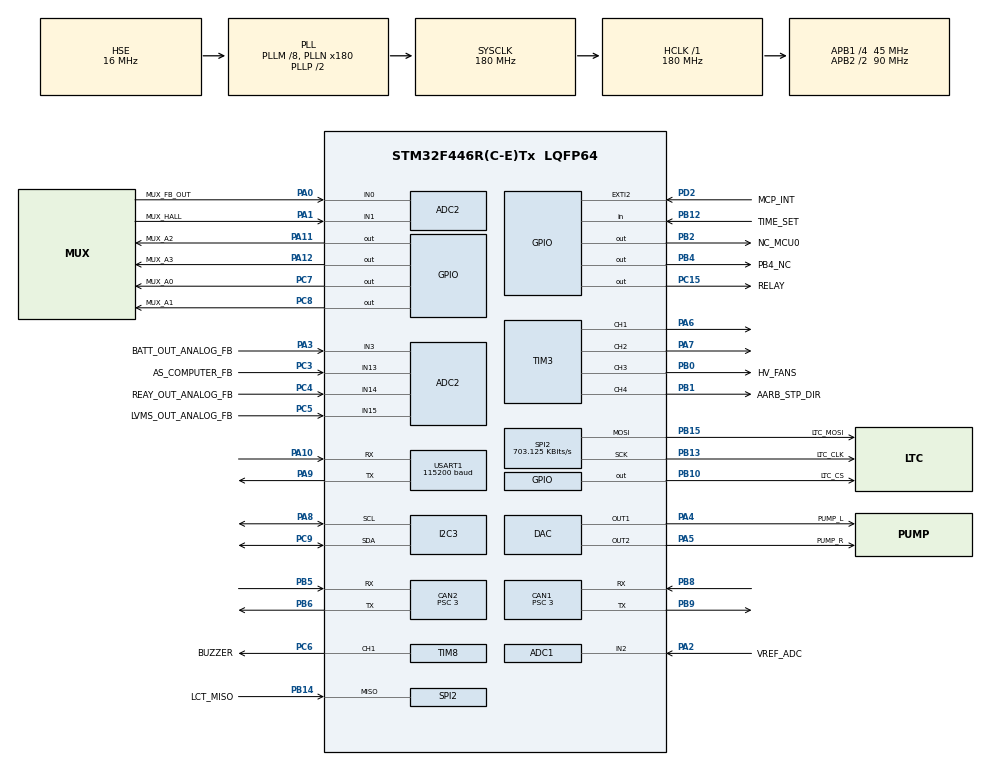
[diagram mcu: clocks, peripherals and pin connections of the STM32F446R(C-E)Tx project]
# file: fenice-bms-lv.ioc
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ADC1.Channel-0\#ChannelRegularConversion=ADC_CHANNEL_VREFINT
ADC1.Channel-1\#ChannelRegularConversion=ADC_CHANNEL_2
ADC1.ContinuousConvMode=DISABLE
ADC1.DMAContinuousRequests=ENABLE
ADC1.EOCSelection=ADC_EOC_SEQ_CONV
ADC1.ExternalTrigConv=ADC_EXTERNALTRIGCONV_T1_CC1
ADC1.NbrOfConversion=2
ADC1.NbrOfConversionFlag=1
ADC1.Rank-0\#ChannelRegularConversion=1
ADC1.Rank-1\#ChannelRegularConversion=2
ADC1.SamplingTime-0\#ChannelRegularConversion=ADC_SAMPLETIME_144CYCLES
ADC1.SamplingTime-1\#ChannelRegularConversion=ADC_SAMPLETIME_144CYCLES
ADC1.master=1
ADC2.Channel-0\#ChannelRegularConversion=ADC_CHANNEL_1
ADC2.Channel-10\#ChannelRegularConversion=ADC_CHANNEL_3
ADC2.Channel-6\#ChannelRegularConversion=ADC_CHANNEL_0
ADC2.Channel-7\#ChannelRegularConversion=ADC_CHANNEL_13
ADC2.Channel-8\#ChannelRegularConversion=ADC_CHANNEL_14
ADC2.Channel-9\#ChannelRegularConversion=ADC_CHANNEL_15
ADC2.DMAContinuousRequests=ENABLE
ADC2.EOCSelection=ADC_EOC_SEQ_CONV
ADC2.ExternalTrigConv=ADC_SOFTWARE_START
ADC2.NbrOfConversion=6
ADC2.NbrOfConversionFlag=1
ADC2.Rank-0\#ChannelRegularConversion=1
ADC2.Rank-10\#ChannelRegularConversion=6
ADC2.Rank-6\#ChannelRegularConversion=2
ADC2.Rank-7\#ChannelRegularConversion=3
ADC2.Rank-8\#ChannelRegularConversion=4
ADC2.Rank-9\#ChannelRegularConversion=5
ADC2.SamplingTime-0\#ChannelRegularConversion=ADC_SAMPLETIME_480CYCLES
ADC2.SamplingTime-10\#ChannelRegularConversion=ADC_SAMPLETIME_144CYCLES
ADC2.SamplingTime-6\#ChannelRegularConversion=ADC_SAMPLETIME_480CYCLES
ADC2.SamplingTime-7\#ChannelRegularConversion=ADC_SAMPLETIME_144CYCLES
ADC2.SamplingTime-8\#ChannelRegularConversion=ADC_SAMPLETIME_144CYCLES
ADC2.SamplingTime-9\#ChannelRegularConversion=ADC_SAMPLETIME_144CYCLES
ADC2.ScanConvMode=ENABLE
CAN1.BS1=CAN_BS1_12TQ
CAN1.BS2=CAN_BS2_2TQ
CAN1.CalculateBaudRate=1000000
CAN1.CalculateTimeBit=1000
CAN1.CalculateTimeQuantum=66.66666666666666
CAN1.Prescaler=3
CAN2.BS1=CAN_BS1_12TQ
CAN2.BS2=CAN_BS2_2TQ
CAN2.CalculateBaudRate=1000000
CAN2.CalculateTimeBit=1000
CAN2.CalculateTimeQuantum=66.66666666666666
CAN2.Prescaler=3
Dma.ADC1.1.Direction=DMA_PERIPH_TO_MEMORY
Dma.ADC1.1.FIFOMode=DMA_FIFOMODE_DISABLE
Dma.ADC1.1.Instance=DMA2_Stream4
Dma.ADC1.1.MemDataAlignment=DMA_MDATAALIGN_HALFWORD
Dma.ADC1.1.MemInc=DMA_MINC_ENABLE
Dma.ADC1.1.Mode=DMA_NORMAL
Dma.ADC1.1.PeriphDataAlignment=DMA_PDATAALIGN_HALFWORD
Dma.ADC1.1.PeriphInc=DMA_PINC_DISABLE
Dma.ADC1.1.Priority=DMA_PRIORITY_LOW
Dma.ADC2.0.Direction=DMA_PERIPH_TO_MEMORY
Dma.ADC2.0.FIFOMode=DMA_FIFOMODE_DISABLE
Dma.ADC2.0.Instance=DMA2_Stream2
Dma.ADC2.0.MemDataAlignment=DMA_MDATAALIGN_HALFWORD
Dma.ADC2.0.MemInc=DMA_MINC_ENABLE
Dma.ADC2.0.Mode=DMA_CIRCULAR
Dma.ADC2.0.PeriphDataAlignment=DMA_PDATAALIGN_HALFWORD
Dma.ADC2.0.PeriphInc=DMA_PINC_DISABLE
Dma.ADC2.0.Priority=DMA_PRIORITY_LOW
Dma.Request0=ADC2
Dma.Request1=ADC1
Mcu.Family=STM32F4
Mcu.Name=STM32F446R(C-E)Tx
Mcu.Package=LQFP64
NVIC.ADC_IRQn=true\:0\:0\:false\:false\:true\:true\:true\:true
NVIC.CAN1_RX0_IRQn=true\:0\:0\:false\:false\:true\:true\:true\:true
NVIC.CAN1_RX1_IRQn=true\:0\:0\:false\:false\:true\:true\:true\:true
NVIC.CAN1_SCE_IRQn=true\:0\:0\:false\:false\:true\:true\:true\:true
NVIC.CAN2_RX0_IRQn=true\:0\:0\:false\:false\:true\:true\:true\:true
NVIC.CAN2_RX1_IRQn=true\:0\:0\:false\:false\:true\:true\:true\:true
NVIC.CAN2_SCE_IRQn=true\:0\:0\:false\:false\:true\:true\:true\:true
NVIC.DMA2_Stream2_IRQn=true\:0\:0\:false\:false\:true\:false\:true\:true
NVIC.DMA2_Stream4_IRQn=true\:0\:0\:false\:false\:true\:false\:true\:true
NVIC.EXTI2_IRQn=true\:0\:0\:false\:false\:true\:true\:true\:true
NVIC.PriorityGroup=NVIC_PRIORITYGROUP_4
NVIC.TIM1_CC_IRQn=true\:0\:0\:false\:false\:true\:true\:true\:true
NVIC.TIM1_UP_TIM10_IRQn=true\:0\:0\:false\:false\:true\:true\:true\:true
NVIC.TIM6_DAC_IRQn=true\:0\:0\:false\:false\:true\:true\:true\:true
NVIC.TIM7_IRQn=true\:0\:0\:false\:false\:true\:true\:true\:true
NVIC.USART1_IRQn=true\:0\:0\:false\:false\:true\:true\:true\:true
PA0-WKUP.GPIO_Label=MUX_FB_OUT
PA0-WKUP.Signal=ADCx_IN0
PA1.GPIO_Label=MUX_HALL
PA1.Signal=ADCx_IN1
PA10.Mode=Asynchronous
PA10.Signal=USART1_RX
PA11.GPIO_Label=MUX_A2
PA11.Signal=GPIO_Output
PA12.GPIO_Label=MUX_A3
PA12.Signal=GPIO_Output
PA13.Mode=Serial_Wire
PA13.Signal=SYS_JTMS-SWDIO
PA14.Mode=Serial_Wire
PA14.Signal=SYS_JTCK-SWCLK
PA2.GPIO_Label=VREF_ADC
PA2.Signal=ADCx_IN2
PA3.GPIO_Label=BATT_OUT_ANALOG_FB
PA3.Signal=ADCx_IN3
PA4.GPIO_Label=PUMP_L
PA4.Signal=COMP_DAC1_group
PA5.GPIO_Label=PUMP_R
PA5.Signal=COMP_DAC2_group
PA6.Signal=S_TIM3_CH1
PA7.Signal=S_TIM3_CH2
PA8.Mode=I2C
PA8.Signal=I2C3_SCL
PA9.Mode=Asynchronous
PA9.Signal=USART1_TX
PB0.GPIO_Label=HV_FANS
PB0.Signal=S_TIM3_CH3
PB1.GPIO_Label=AARB_STP_DIR
PB1.Signal=S_TIM3_CH4
PB10.GPIO_Label=LTC_CS
PB10.Signal=GPIO_Output
PB12.GPIO_Label=TIME_SET
PB12.Signal=GPIO_Input
PB13.GPIO_Label=LTC_CLK
PB13.Mode=Full_Duplex_Master
PB13.Signal=SPI2_SCK
PB14.GPIO_Label=LCT_MISO
PB14.Mode=Full_Duplex_Master
PB14.Signal=SPI2_MISO
PB15.GPIO_Label=LTC_MOSI
PB15.Mode=Full_Duplex_Master
PB15.Signal=SPI2_MOSI
PB2.GPIO_Label=NC_MCU0
PB2.Signal=GPIO_Output
PB3.Signal=SYS_JTDO-SWO
PB4.GPIO_Label=PB4_NC
PB4.Signal=GPIO_Output
PB5.Mode=CAN_Activate
PB5.Signal=CAN2_RX
PB6.Mode=CAN_Activate
PB6.Signal=CAN2_TX
PB8.Mode=CAN_Activate
PB8.Signal=CAN1_RX
PB9.Mode=CAN_Activate
PB9.Signal=CAN1_TX
PC15-OSC32_OUT.GPIO_Label=RELAY
PC15-OSC32_OUT.Signal=GPIO_Output
PC3.GPIO_Label=AS_COMPUTER_FB
PC3.Signal=ADCx_IN13
PC4.GPIO_Label=REAY_OUT_ANALOG_FB
PC4.Signal=ADCx_IN14
PC5.GPIO_Label=LVMS_OUT_ANALOG_FB
PC5.Signal=ADCx_IN15
PC6.GPIO_Label=BUZZER
PC6.Signal=S_TIM8_CH1
PC7.GPIO_Label=MUX_A0
PC7.Signal=GPIO_Output
PC8.GPIO_Label=MUX_A1
PC8.Signal=GPIO_Output
PC9.Mode=I2C
PC9.Signal=I2C3_SDA
PD2.GPIO_Label=MCP_INT
PD2.Signal=GPXTI2
PH0-OSC_IN.Mode=HSE-External-Oscillator
PH0-OSC_IN.Signal=RCC_OSC_IN
PH1-OSC_OUT.Mode=HSE-External-Oscillator
PH1-OSC_OUT.Signal=RCC_OSC_OUT
ProjectManager.HeapSize=0x200
ProjectManager.StackSize=0x400
ProjectManager.TargetToolchain=Makefile
RCC.AHBFreq_Value=180000000
RCC.APB1CLKDivider=RCC_HCLK_DIV4
RCC.APB1Freq_Value=45000000
RCC.APB1TimFreq_Value=90000000
RCC.APB2CLKDivider=RCC_HCLK_DIV2
RCC.APB2Freq_Value=90000000
RCC.APB2TimFreq_Value=180000000
RCC.CortexFreq_Value=180000000
RCC.HCLKFreq_Value=180000000
RCC.HSE_VALUE=16000000
RCC.PLLM=8
RCC.PLLN=180
RCC.PLLSourceVirtual=RCC_PLLSOURCE_HSE
RCC.SYSCLKFreq_VALUE=180000000
RCC.SYSCLKSource=RCC_SYSCLKSOURCE_PLLCLK
RCC.USBFreq_Value=180000000
RCC.VCOOutputFreq_Value=360000000
SH.ADCx_IN0.0=ADC2_IN0,IN0
SH.ADCx_IN1.0=ADC2_IN1,IN1
SH.ADCx_IN13.0=ADC2_IN13,IN13
SH.ADCx_IN14.0=ADC2_IN14,IN14
SH.ADCx_IN15.0=ADC2_IN15,IN15
SH.ADCx_IN2.0=ADC1_IN2,IN2
SH.ADCx_IN3.0=ADC2_IN3,IN3
SH.COMP_DAC1_group.0=DAC_OUT1,DAC_OUT1
SH.COMP_DAC2_group.0=DAC_OUT2,DAC_OUT2
SH.S_TIM3_CH1.0=TIM3_CH1,PWM Generation1 CH1
SH.S_TIM3_CH2.0=TIM3_CH2,PWM Generation2 CH2
SH.S_TIM3_CH3.0=TIM3_CH3,PWM Generation3 CH3
SH.S_TIM3_CH4.0=TIM3_CH4,PWM Generation4 CH4
SH.S_TIM8_CH1.0=TIM8_CH1,PWM Generation1 CH1
SPI2.BaudRatePrescaler=SPI_BAUDRATEPRESCALER_64
SPI2.CLKPhase=SPI_PHASE_2EDGE
SPI2.CLKPolarity=SPI_POLARITY_HIGH
SPI2.CalculateBaudRate=703.125 KBits/s
SPI2.Direction=SPI_DIRECTION_2LINES
SPI2.Mode=SPI_MODE_MASTER
SPI2.VirtualType=VM_MASTER
TIM1.Channel-Output\ Compare1\ No\ Output=TIM_CHANNEL_1
TIM1.CounterMode=TIM_COUNTERMODE_DOWN
TIM1.OCMode_1=TIM_OCMODE_ACTIVE
TIM1.Prescaler=1
TIM1.TIM_MasterOutputTrigger=TIM_TRGO_RESET
TIM10.Prescaler=36000 - 1
TIM3.Channel-PWM\ Generation1\ CH1=TIM_CHANNEL_1
TIM3.Channel-PWM\ Generation2\ CH2=TIM_CHANNEL_2
TIM3.Channel-PWM\ Generation3\ CH3=TIM_CHANNEL_3
TIM3.Channel-PWM\ Generation4\ CH4=TIM_CHANNEL_4
TIM7.Prescaler=9000 - 1
TIM8.Channel-PWM\ Generation1\ CH1=TIM_CHANNEL_1
TIM8.Prescaler=36000
USART1.BaudRate=115200
USART1.VirtualMode=VM_ASYNC
VP_ADC1_Vref_Input.Mode=IN-Vrefint
VP_TIM10_VS_ClockSourceINT.Mode=Enable_Timer
VP_TIM1_VS_ClockSourceINT.Mode=Internal
VP_TIM1_VS_no_output1.Mode=Output Compare1 No Output
VP_TIM3_VS_ClockSourceINT.Mode=Internal
VP_TIM7_VS_ClockSourceINT.Mode=Enable_Timer
VP_TIM8_VS_ClockSourceINT.Mode=Internal
board=custom

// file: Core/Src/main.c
/* USER CODE BEGIN Header */
/**
 ******************************************************************************
 * @file           : main.c
 * @brief          : Main program body
 ******************************************************************************
 * @attention
 *
 * Copyright (c) 2023 STMicroelectronics.
 * All rights reserved.
 *
 * This software is licensed under terms that can be found in the LICENSE file
 * in the root directory of this software component.
 * If no LICENSE file comes with this software, it is provided AS-IS.
 *
 ******************************************************************************
 */
/* USER CODE END Header */
#include "main.h"

#include "adc.h"
#include "can.h"
#include "dac.h"
#include "dma.h"
#include "gpio.h"
#include "i2c.h"
#include "spi.h"
#include "tim.h"
#include "usart.h"

/* USER CODE BEGIN Includes */
#include "bms_fsm.h"
/* USER CODE END Includes */

/* USER CODE BEGIN PV */

uint32_t get_current_time_ms(void) {
    return HAL_GetTick();
}

void blocking_delay_ms(uint32_t ms) {
    HAL_Delay(ms);
}

/* USER CODE END PV */

void SystemClock_Config(void);

/* USER CODE BEGIN 0 */

state_t cur_state = STATE_INIT;

/* USER CODE END 0 */

int main(void) {

    /* MCU Configuration--------------------------------------------------------*/

    /* Reset of all peripherals, Initializes the Flash interface and the Systick. */
    HAL_Init();

    /* Configure the system clock */
    SystemClock_Config();

    /* Initialize all configured peripherals */
    MX_GPIO_Init();
    MX_DMA_Init();
    MX_CAN2_Init();
    MX_DAC_Init();
    MX_I2C3_Init();
    MX_SPI2_Init();
    MX_USART1_UART_Init();
    MX_CAN1_Init();
    MX_ADC2_Init();
    MX_ADC1_Init();
    MX_TIM1_Init();
    MX_TIM3_Init();
    MX_TIM8_Init();
    MX_TIM7_Init();
    MX_TIM10_Init();

    /* Infinite loop */
    /* USER CODE BEGIN WHILE */
    while (1) {
        cur_state = run_state(cur_state, NULL);

        /* USER CODE END WHILE */

    }
}

void SystemClock_Config(void) {
    RCC_OscInitTypeDef RCC_OscInitStruct = {0};
    RCC_ClkInitTypeDef RCC_ClkInitStruct = {0};

    /** Configure the main internal regulator output voltage
  */
    __HAL_RCC_PWR_CLK_ENABLE();
    __HAL_PWR_VOLTAGESCALING_CONFIG(PWR_REGULATOR_VOLTAGE_SCALE1);

    /** Initializes the RCC Oscillators according to the specified parameters
  * in the RCC_OscInitTypeDef structure.
  */
    RCC_OscInitStruct.OscillatorType = RCC_OSCILLATORTYPE_HSE;
    RCC_OscInitStruct.HSEState       = RCC_HSE_ON;
    RCC_OscInitStruct.PLL.PLLState   = RCC_PLL_ON;
    RCC_OscInitStruct.PLL.PLLSource  = RCC_PLLSOURCE_HSE;
    RCC_OscInitStruct.PLL.PLLM       = 8;
    RCC_OscInitStruct.PLL.PLLN       = 180;
    RCC_OscInitStruct.PLL.PLLP       = RCC_PLLP_DIV2;
    RCC_OscInitStruct.PLL.PLLQ       = 2;
    RCC_OscInitStruct.PLL.PLLR       = 2;
    if (HAL_RCC_OscConfig(&RCC_OscInitStruct) != HAL_OK) {
        Error_Handler();
    }

    /** Activate the Over-Drive mode
  */
    if (HAL_PWREx_EnableOverDrive() != HAL_OK) {
        Error_Handler();
    }

    /** Initializes the CPU, AHB and APB buses clocks
  */
    RCC_ClkInitStruct.ClockType      = RCC_CLOCKTYPE_HCLK | RCC_CLOCKTYPE_SYSCLK | RCC_CLOCKTYPE_PCLK1 | RCC_CLOCKTYPE_PCLK2;
    RCC_ClkInitStruct.SYSCLKSource   = RCC_SYSCLKSOURCE_PLLCLK;
    RCC_ClkInitStruct.AHBCLKDivider  = RCC_SYSCLK_DIV1;
    RCC_ClkInitStruct.APB1CLKDivider = RCC_HCLK_DIV4;
    RCC_ClkInitStruct.APB2CLKDivider = RCC_HCLK_DIV2;

    if (HAL_RCC_ClockConfig(&RCC_ClkInitStruct, FLASH_LATENCY_5) != HAL_OK) {
        Error_Handler();
    }
}

void Error_Handler(void) {
    /* USER CODE BEGIN Error_Handler_Debug */
#ifdef BMS_LV_SHUTDOWN_IF_ERROR
    set_discharge(0);
    set_rfe_frg(0);
    set_relay(0);
#endif
    /* User can add his own implementation to report the HAL error return state */
    __disable_irq();
    while (1) {
    }
    /* USER CODE END Error_Handler_Debug */
}

#ifdef USE_FULL_ASSERT
/**
  * @brief  Reports the name of the source file and the source line number
  *         where the assert_param error has occurred.
  * @param  file: pointer to the source file name
  * @param  line: assert_param error line source number
  * @retval None
  */
void assert_failed(uint8_t *file, uint32_t line) {
    /* USER CODE BEGIN 6 */
    /* User can add his own implementation to report the file name and line
   number, ex: printf("Wrong parameters value: file %s on line %d\r\n", file,
   line) */
    /* USER CODE END 6 */
}
#endif /* USE_FULL_ASSERT */
